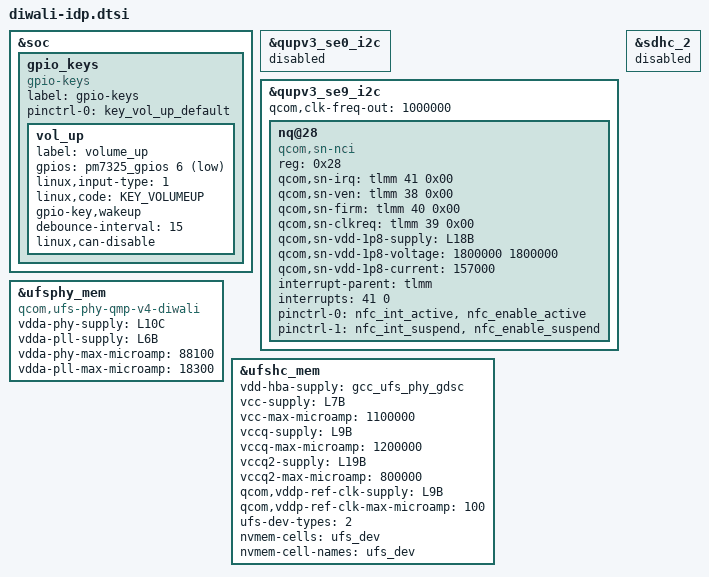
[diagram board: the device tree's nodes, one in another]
#include <dt-bindings/gpio/gpio.h>
#include <dt-bindings/input/input.h>

#include "diwali-pmic-overlay.dtsi"
#include "diwali-thermal-overlay.dtsi"

&soc {
	gpio_keys {
		compatible = "gpio-keys";
		label = "gpio-keys";

		pinctrl-names = "default";
		pinctrl-0 = <&key_vol_up_default>;

		vol_up {
			label = "volume_up";
			gpios = <&pm7325_gpios 6 GPIO_ACTIVE_LOW>;
			linux,input-type = <1>;
			linux,code = <KEY_VOLUMEUP>;
			gpio-key,wakeup;
			debounce-interval = <15>;
			linux,can-disable;
		};
	};
};

&qupv3_se0_i2c {
	status = "disabled";
};

&qupv3_se9_i2c {
	status = "ok";
	qcom,clk-freq-out = <1000000>;
	#address-cells = <1>;
	#size-cells = <0>;
	nq@28 {
		compatible = "qcom,sn-nci";
		reg = <0x28>;
		qcom,sn-irq = <&tlmm 41 0x00>;
		qcom,sn-ven = <&tlmm 38 0x00>;
		qcom,sn-firm = <&tlmm 40 0x00>;
		qcom,sn-clkreq = <&tlmm 39 0x00>;
		qcom,sn-vdd-1p8-supply = <&L18B>;
		qcom,sn-vdd-1p8-voltage = <1800000 1800000>;
		qcom,sn-vdd-1p8-current = <157000>;
		interrupt-parent = <&tlmm>;
		interrupts = <41 0>;
		interrupt-names = "nfc_irq";
		pinctrl-names = "nfc_active", "nfc_suspend";
		pinctrl-0 = <&nfc_int_active &nfc_enable_active>;
		pinctrl-1 = <&nfc_int_suspend &nfc_enable_suspend>;
	};
};

&sdhc_2 {
	status = "disabled";
};

&ufsphy_mem {
	compatible = "qcom,ufs-phy-qmp-v4-diwali";

	vdda-phy-supply = <&L10C>;
	vdda-pll-supply = <&L6B>;
	vdda-phy-max-microamp = <88100>;
	vdda-pll-max-microamp = <18300>;

	status = "ok";
};

&ufshc_mem {
	vdd-hba-supply = <&gcc_ufs_phy_gdsc>;

	vcc-supply = <&L7B>;
	vcc-max-microamp = <1100000>;

	vccq-supply = <&L9B>;
	vccq-max-microamp = <1200000>;

	vccq2-supply = <&L19B>;
	vccq2-max-microamp = <800000>;

	qcom,vddp-ref-clk-supply = <&L9B>;
	qcom,vddp-ref-clk-max-microamp = <100>;

	/*
	 * ufs-dev-types and nvmem entries are for ufs device
	 * identification using nvmem interface. Use number of
	 * ufs devices supported for ufs-dev-types, and nvmem handle
	 * added by pmic for sdam register.
	 */
	ufs-dev-types = <2>;
	nvmem-cells = <&ufs_dev>;
	nvmem-cell-names = "ufs_dev";

	status = "ok";
};


